# RTS5918 register map
Vendor: Realtek Semiconductor Corp.; Series: RTS5918 Series; File version: 1.00
CPU: ARMV8MML r0p0, little endian, MPU, FPU, VTOR, 3 interrupt priority bits, 8 SAU regions
Registers are 32-bit, read-write, reset 0x0 unless marked. A register's access mark holds for its fields unless they carry their own. Offsets are from the block's base; [hi:lo] are bit positions; {n}, {i} and the like mark numbered series.

## PS2 — PS2 Controller
Base 0x40254300
Same registers: PS2_2 0x40254400, PS2_3 0x40255700
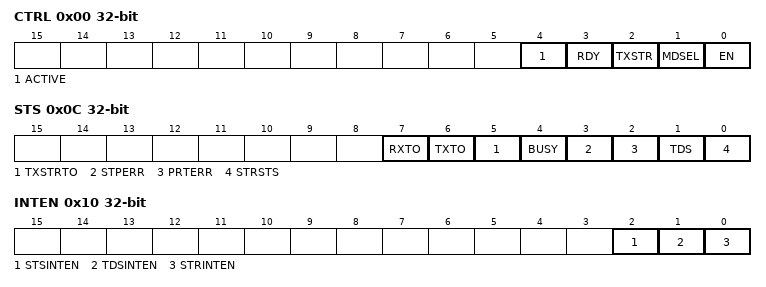
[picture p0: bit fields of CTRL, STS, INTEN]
0x00 CTRL — CONTROL REGISTER
  [4] ACTIVE — PS/2 Controller Operate Stage
    0=RESET (Set PS/2 controller to reset stage); 1=ACTIVE (Set controller to active stage)
  [3] RDY ro — Ready to Transmit or Not
    0=NOT_READY (PS/2 controller is not ready to transmit); 1=READY (PS/2 controller is ready to transmit)
  [2] TXSTR — Kick PS/2 Controller Start to Transmit
  [1] MDSEL — Accessing Mode Selection
    0=RECEIVE (Set PS/2 controller to receive mode); 1=TRANSMIT (Set PS/2 controller to transmit mode)
  [0] EN — Enable PS/2 Controller
    0=DISABLE (Disable PS/2 controller); 1=ENABLE (Enable PS/2 controller)
0x04 TX — TRANSMIT DATA REGISTER
  [7:0] DATA — PS/2 Transmit Data
0x08 RX — RECEIVE DATA REGISTER
  [7:0] DATA — PS/2 Receive Data Buffer
0x0C STS — STATUS REGISTER
  [7] RXTO write-1-clears — Receive Timeout Status
    0=NOT_OCCURRED (Receive timeout is not occurred); 1=OCCURRED (Receive timeout is occurred)
  [6] TXTO write-1-clears — Transmit Timeout Status
    0=NOT_OCCURRED (Transmit timeout is not occurred); 1=OCCURRED (Transmit timeout is occurred)
  [5] TXSTRTO write-1-clears — Transmit Start Timeout Status
    0=NOT_OCCURRED (Transmit start timeout is not occurred); 1=OCCURRED (Transmit start timeout is occurred)
  [4] BUSY ro — Busy Status
  [3] STPERR write-1-clears — Stop-bit Error Status
    0=NOT_OCCURRED (Stop-bit error is not occurred); 1=OCCURRED (Stop-bit error is occurred)
  [2] PRTERR write-1-clears — Parity-bit Error Status
    0=NOT_OCCURRED (Parity-bit error is not occurred); 1=OCCURRED (Parity-bit error is occurred)
  [1] TDS write-1-clears — Transcation Done Status
    0=NOT_OCCURRED (Transcation done is not occurred); 1=OCCURRED (Transcation done is occurred)
  [0] STRSTS write-1-clears — Strat-bit Detection Status
    0=NOT_OCCURRED (Strat-bit detection is not occurred); 1=OCCURRED (Strat-bit detection is occurred)
0x10 INTEN — INTERRUPT ENABLE REGISTER
  [2] STSINTEN — Enable Status Interrupt
    0=DISABLE (Disable status interrupt); 1=ENABLE (Enable status interrupt)
  [1] TDSINTEN — Enable Transmit Done Interrupt
    0=DISABLE (Disable transmit done interrupt); 1=ENABLE (Enable transmit done interrupt)
  [0] STRINTEN — Enable Start-bit Detection Interrupt
    0=DISABLE (Disable start-bit detection interrupt); 1=ENABLE (Enable start-bit detection interrupt)

## KBM — Keyboard Matrix Controller
Base 0x40254200
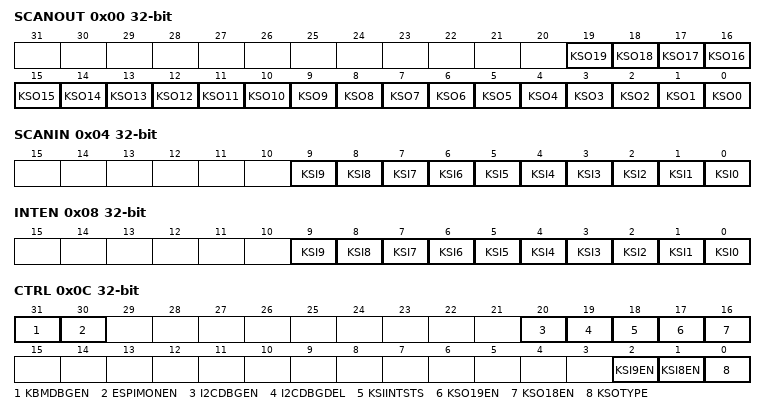
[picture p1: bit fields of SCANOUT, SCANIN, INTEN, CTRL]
0x00 SCANOUT — SCAN OUT CONTROL REGISTER
  [n] KSO{n} (n=0..19) — KSO Output Level
    0=LOW (KSO output low); 1=HIGH (KSO output high)
0x04 SCANIN ro — SACN INPUT STATUS REGISTER
  [n] KSI{n} (n=0..9) — KSI Input Level
    0=LOW (KSI input is low); 1=HIGH (KSI input is high)
0x08 INTEN — INTERRUPT ENABLE REGISTER
  [n] KSI{n} (n=0..9) — KSI Interrupt Enable
    0=DISABLE (KSI interrupt disable); 1=ENABLE (KSI interrupt enable)
0x0C CTRL — CONTROL REGISTER
  [31] KBMDBGEN — KBM Debug Enable
    0=DISABLE (Disable KBM Debug); 1=ENABLE (Enable KBM Debug)
  [30] ESPIMONEN — ESPI Monitor Enable
    0=DISABLE (Disable ESPI Monitor); 1=ENABLE (Enable ESPI Monitor)
  [20] I2CDBGEN — I2C Debug Enable
    0=DISABLE (Disable I2C Debug); 1=ENABLE (Enable I2C Debug)
  [19] I2CDBGDEL — I2C Debug Select
    0=I2CDBG (KBM I2C Debug); 1=I2CDBGREG (I2C Debug Refer Bit20)
  [18] KSIINTSTS — KSI Interrupt Status
    0=NOT_OCCURRED (KSI interrupt is not occurred); 1=OCCURRED (KSI interrupt is occurred)
  [17] KSO19EN — Enable KSO19
    0=DISABLE (Disable KSO19); 1=ENABLE (Enable KSO19)
  [16] KSO18EN — Enable KSO18
    0=DISABLE (Disable KSO18); 1=ENABLE (Enable KSO18)
  [2] KSI9EN — Enable KSI9
    0=DISABLE (Disable KSI9); 1=ENABLE (Enable KSI9)
  [1] KSI8EN — Enable KSI8
    0=DISABLE (Disable KSI8); 1=ENABLE (Enable KSI8)
  [0] KSOTYPE — Output Type of KSO pin
    0=PUSH_PULL; 1=OPEN_DRAIN
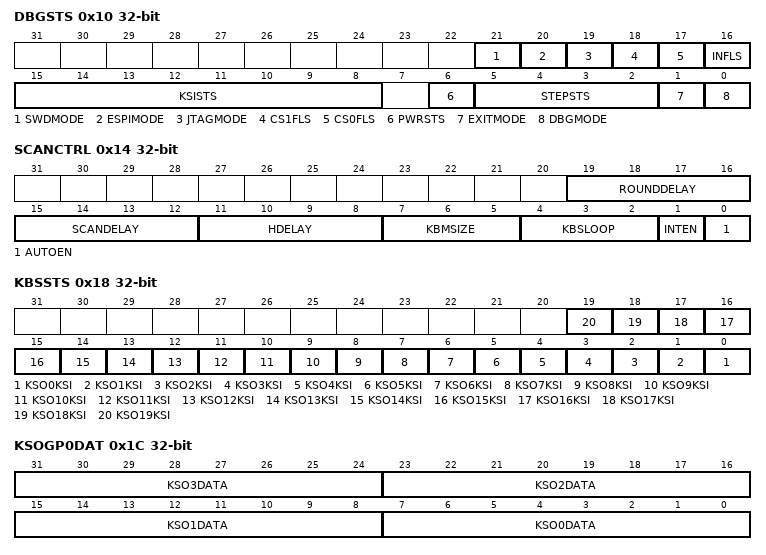
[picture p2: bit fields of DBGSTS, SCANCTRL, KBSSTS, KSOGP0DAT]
0x10 DBGSTS ro — DWBUG STATUS REGISTER
  [21] SWDMODE — SWD Mode Select
    0=NONE (Not in SWD Mode); 1=SELECTED (SWD Mode)
  [20] ESPIMODE — eSPI Mode Select
    0=NONE (Not in eSPI Mode); 1=SELECTED (eSPI Mode)
  [19] JTAGMODE — Jtag Mode Select
    0=NONE (Not in Jtag Mode); 1=SELECTED (Jtag Mode)
  [18] CS1FLS — CS1 Flash Select
    0=NONE (Not in CS1 Flash Mode); 1=SELECTED (CS1 Flash Mode)
  [17] CS0FLS — CS0 Flash Select
    0=NONE (Not in CS0 Flash Mode); 1=SELECTED (CS0 Flash Mode)
  [16] INFLS — Internal Flash Select
    0=NONE (Not in Internal Flash Mode); 1=SELECTED (Internal Flash Mode)
  [15:8] KSISTS — KSIs Status
  [6] PWRSTS — KBM Power Status
    0=NOPWR (KBM without Power); 1=POWER (KBM Powered)
  [5:2] STEPSTS — Entry Debug Status
  [1] EXITMODE — Exit Debug Mode Status
    0=NORMAL (Normal Operation); 1=EXIT (Exit Debug Mode)
  [0] DBGMODE — Debug Mode Status
    0=NORMAL (Normal Operation); 1=DEBUG (In Debug Mode)
0x14 SCANCTRL — KB SCAN CONTROL REGISTER
  [19:16] ROUNDDELAY — SCAN ROUND DELAY
  [15:12] SCANDELAY — KSI SCAN DELAY
    0=11US; 1=13US; 2=15US; 3=17US; 4=19US; 5=21US; 6=23US; 7=25US; 8=27US; 9=29US
  [11:8] HDELAY — KSO HIGH DELAY
    0=23US; 1=31US; 2=39US; 3=47US; 4=55US; 5=64US; 6=71US; 7=79US; 8=87US; 9=95US
  [7:5] KBMSIZE — KBS MATRIX SIZE
    {v}=8X{v+16} ({v+16} KSOs) (v=0..4)
  [4:2] KBSLOOP — KBS AUTO SCAN LOOP
    {v}={v+1} Round (v=0..7)
  [1] INTEN — KBS AUTO SCAN INTERRUPT ENABLE
    0=LOW (Disable KBS Interrupt); 1=HIGH (Eable KBS Interrupt)
  [0] AUTOEN — KBS AUTO SCAN ENABLE
    0=LOW (Disable KBS); 1=HIGH (Eable KBS)
0x18 KBSSTS — KBSCAN STATUS REGISTER
  [n] KSO{n}KSI (n=0..19) — KSO Sampling SKI status
0x1C KSOGP0DAT ro — KSO GROUP0 DATA REGISTER
  [8n+7:8n] KSO{n}DATA (n=0..3)
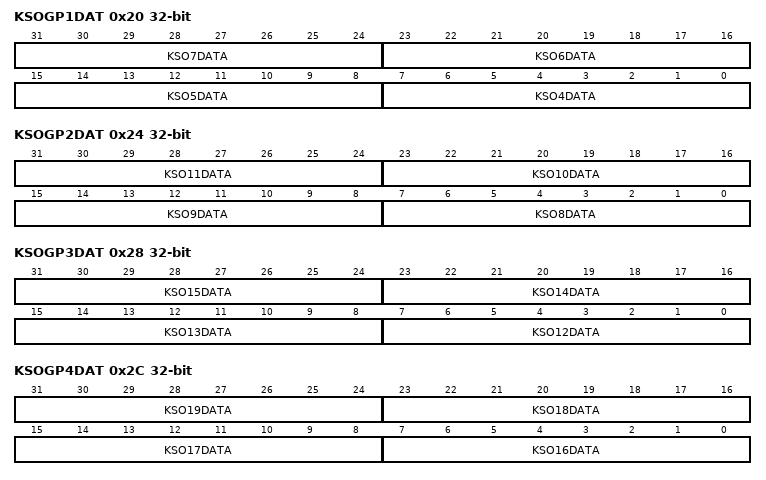
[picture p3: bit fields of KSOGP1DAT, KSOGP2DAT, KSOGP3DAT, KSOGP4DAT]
0x20 KSOGP1DAT ro — KSO GROUP1 DATA REGISTER
  [8n-25:8n-32] KSO{n}DATA (n=4..7)
0x24 KSOGP2DAT ro — KSO GROUP2 DATA REGISTER
  [8n-57:8n-64] KSO{n}DATA (n=8..11)
0x28 KSOGP3DAT ro — KSO GROUP3 DATA REGISTER
  [8n-89:8n-96] KSO{n}DATA (n=12..15)
0x2C KSOGP4DAT ro — KSO GROUP4 DATA REGISTER
  [8n-121:8n-128] KSO{n}DATA (n=16..19)
